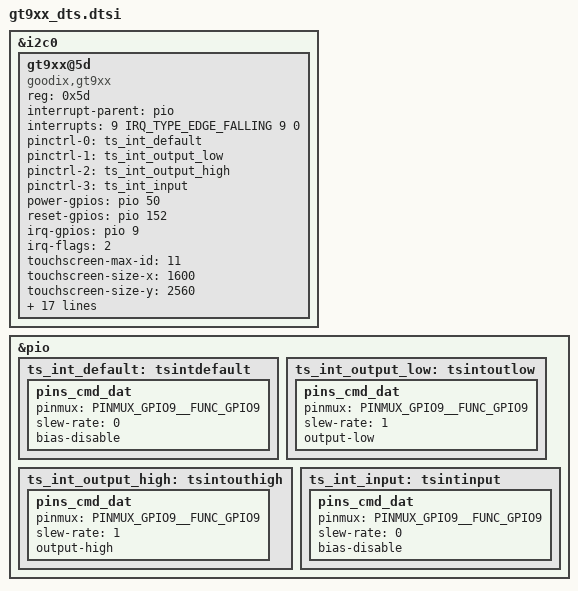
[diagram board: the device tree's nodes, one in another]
// SPDX-License-Identifier: GPL-2.0+
/*
 * Copyright (c) 2019 MediaTek Inc.
 */
&i2c0 {
	gt9xx@5d {
		compatible = "goodix,gt9xx";
		reg = <0x5d>; 
		status = "okay";
		interrupt-parent = <&pio>;
		interrupts = <9 IRQ_TYPE_EDGE_FALLING 9 0>;
		pinctrl-names = "default", "int-output-low","int-output-high", "int-input";
		pinctrl-0 = <&ts_int_default>;
		pinctrl-1 = <&ts_int_output_low>;
		pinctrl-2 = <&ts_int_output_high>;
		pinctrl-3 = <&ts_int_input>;
	
		power-gpios = <&pio 50 0>;
		reset-gpios = <&pio 152 0>;
		irq-gpios = <&pio 9 0>;
		irq-flags = <2>;
	
		touchscreen-max-id = <11>;
		touchscreen-size-x = <1600>;
		touchscreen-size-y = <2560>;
		touchscreen-max-w = <512>;
		touchscreen-max-p = <512>;
		touchscreen-key-map = <172>, <158>; /*KEY_HOMEPAGE=172, KEY_BACK=158，KEY_MENU=139*/
		goodix,slide-wakeup = <0>;
		goodix,type-a-report = <0>;
		goodix,driver-send-cfg = <1>;
		goodix,resume-in-workqueue = <0>;
		goodix,int-sync = <1>;
		goodix,swap-x2y = <1>;
		goodix,reverse-x = <1>;
		goodix,reverse-y = <0>;
		goodix,esd-protect = <1>;
                goodix,auto-update-cfg = <0>;
/*
		goodix,auto-update-cfg = <1>;
                goodix,auto-update = <1>;
*/
		goodix,power-off-sleep = <0>;
		goodix,pen-suppress-finger = <0>;
		goodix,cfg-group0 = [
			 00 00 0A 40 06 0A 0D 00 01 08 28 05 50 32 03 05 00 00 00 00 00 00 00 00 00 00 00 8C 2C 0E 1B 19 F4 0A 00 00 01 B9 04 1D 00 00 00 00 00 03 64 32 00 00 00 11 35 94 C5 02 07 00 00 04 A4 13 00 85 18 00 6E 1E 00 5C 25 00 4D 2F 00 4D 00 00 00 00 00 00 00 00 00 00 00 00 00 00 00 00 00 00 00 00 00 00 00 00 00 00 00 00 00 00 00 00 00 00 00 00 02 04 06 08 0A 0C 0E 10 12 14 16 18 1A 1C 00 00 00 00 00 00 00 00 00 00 00 00 00 00 00 00 00 02 04 06 08 0A 0C 0F 10 12 13 14 28 26 24 22 21 20 1F 1E 1D 1C 18 16 FF FF 00 00 00 00 00 00 00 00 00 00 00 00 00 00 00 00 CC 01
		];
	};
};

&pio {
	ts_int_default: tsintdefault {
		pins_cmd_dat {
			pinmux = <PINMUX_GPIO9__FUNC_GPIO9>;
			slew-rate = <0>;
			bias-disable;
		};
	};
	ts_int_output_low: tsintoutlow {
		pins_cmd_dat {
			pinmux = <PINMUX_GPIO9__FUNC_GPIO9>;
			slew-rate = <1>;
			output-low;
		};
	};
	ts_int_output_high: tsintouthigh {
		pins_cmd_dat {
			pinmux = <PINMUX_GPIO9__FUNC_GPIO9>;
			slew-rate = <1>;
			output-high;
		};
	};
	ts_int_input: tsintinput {
		pins_cmd_dat {
			pinmux = <PINMUX_GPIO9__FUNC_GPIO9>;
			slew-rate = <0>;
			bias-disable;
		};
	};
};
